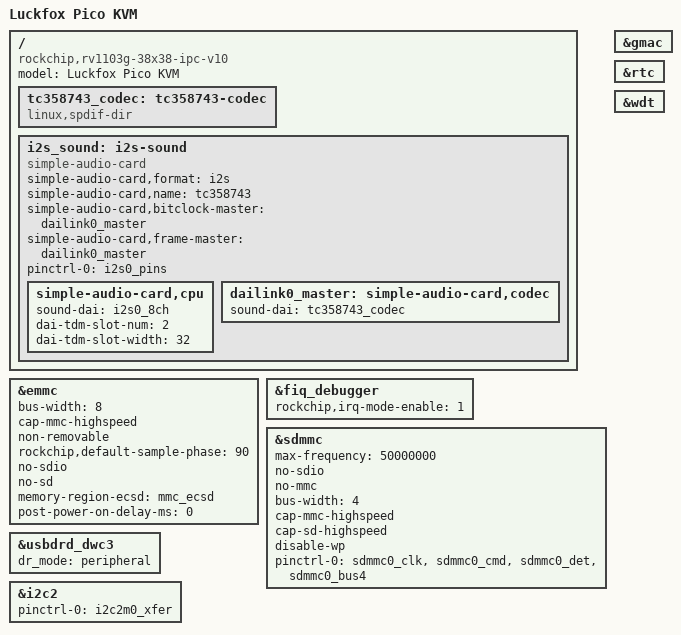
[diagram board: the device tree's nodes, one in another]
// SPDX-License-Identifier: (GPL-2.0+ OR MIT)
/*
 * Copyright (c) 2022 Rockchip Electronics Co., Ltd.
 */

/dts-v1/;
#include "rv1106.dtsi"
#include "rv1106-luckfox-pico-kvm-ipc.dtsi"
#include <dt-bindings/input/input.h>
#include <dt-bindings/display/media-bus-format.h>

/ {
	model = "Luckfox Pico KVM";
	compatible = "rockchip,rv1103g-38x38-ipc-v10", "rockchip,rv1106g3";
	
	tc358743_codec: tc358743-codec {
		#sound-dai-cells = <0>;
		//compatible = "dmic-codec";
		compatible = "linux,spdif-dir";
		status = "okay";
	};

	i2s_sound: i2s-sound {	
		compatible = "simple-audio-card";
		simple-audio-card,format = "i2s";
		simple-audio-card,name = "tc358743";
		simple-audio-card,bitclock-master = <&dailink0_master>;
		simple-audio-card,frame-master = <&dailink0_master>;
		status = "okay";
		pinctrl-names = "default";
		pinctrl-0 = <&i2s0_pins>;
		
		simple-audio-card,cpu {
			sound-dai = <&i2s0_8ch>;
			dai-tdm-slot-num = <2>;
			dai-tdm-slot-width = <32>;
		};
		dailink0_master: simple-audio-card,codec {
			sound-dai = <&tc358743_codec>;
		};
	};

};

/**********CRU**********/
//&cru {
//	assigned-clocks =
//		<&cru PLL_GPLL>, <&cru PLL_CPLL>,
//		<&cru ARMCLK>,
//		<&cru ACLK_PERI_ROOT>, <&cru HCLK_PERI_ROOT>,
//		<&cru PCLK_PERI_ROOT>, <&cru ACLK_BUS_ROOT>,
//		<&cru PCLK_TOP_ROOT>, <&cru PCLK_PMU_ROOT>,
//		<&cru HCLK_PMU_ROOT>, <&cru CLK_500M_SRC>;
//	assigned-clock-rates =
//		<1188000000>, <700000000>,
//		<1104000000>,
//		<400000000>, <200000000>,
//		<100000000>, <300000000>,
//		<100000000>, <100000000>,
//		<200000000>, <700000000>;
//};

/**********NPU**********/
//&npu {
//	assigned-clock-rates = <700000000>;
//};

/**********EMMC**********/
&emmc {
	bus-width = <8>;
	cap-mmc-highspeed;
	non-removable;
	// mmc-hs200-1_8v;
	rockchip,default-sample-phase = <90>;
	no-sdio;
	no-sd;
	memory-region-ecsd = <&mmc_ecsd>;
	post-power-on-delay-ms = <0>;
	status = "okay";
};

&fiq_debugger {
	rockchip,irq-mode-enable = <1>;
	status = "okay";
};

/**********SDCARD**********/
&sdmmc {
	max-frequency = <50000000>;
	no-sdio;
	no-mmc;
	bus-width = <4>;
	cap-mmc-highspeed;
	cap-sd-highspeed;
	disable-wp;
	pinctrl-names = "default";
	pinctrl-0 = <&sdmmc0_clk &sdmmc0_cmd &sdmmc0_det &sdmmc0_bus4>;
	status = "okay";
};

/**********ETH**********/
&gmac {
	status = "okay";
};

/**********USB**********/
&usbdrd_dwc3 {
	status = "okay";
	dr_mode = "peripheral";
};

/**********RTC**********/
&rtc {
	status = "okay";
};

/**********LCD**********/
&i2c2 {
	status = "okay";
	pinctrl-names = "default";
	pinctrl-0 = <&i2c2m0_xfer>;	
};


/********Watchdog*******/
&wdt {
	status = "okay";
};
